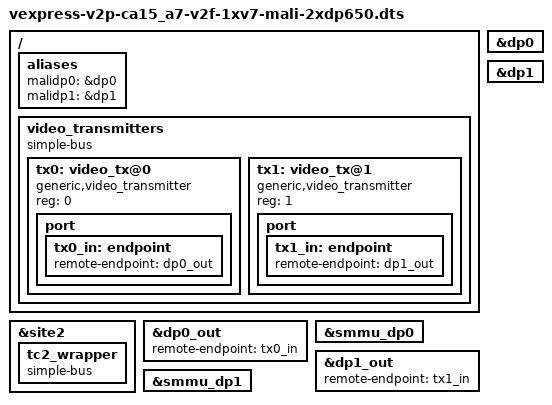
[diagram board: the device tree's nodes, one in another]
/*
 * ARM Versatile Express development platform with an A15x2 A7x3 CoreTile
 * and a single Virtex 7 LogicTile.
 * Configured for a bitfile containing a dual-display DP650 and
 * corresponding MMU-500s
 */

#include "vexpress-v2p-ca15_a7.dts"

/ {
	aliases {
		malidp0 = &dp0;
		malidp1 = &dp1;
	};

	video_transmitters {
		compatible = "simple-bus";
		#address-cells = <1>;
		#size-cells = <0>;

		tx0: video_tx@0 {
			compatible = "generic,video_transmitter";
			reg = <0>;
			port {
				tx0_in: endpoint {
					remote-endpoint = <&dp0_out>;
				};
			};
		};

		tx1: video_tx@1 {
			compatible = "generic,video_transmitter";
			reg = <1>;
			port {
				tx1_in: endpoint {
					remote-endpoint = <&dp1_out>;
				};
			};
		};
	};
};

&site2 {
	tc2_wrapper {
		compatible = "simple-bus";
		#address-cells = <1>;
		#size-cells = <1>;
		/*
		 * On VE TC2, all of the APB slaves are shifted up to
		 * 0x70000000.
		 * So we map 0 to (0x40000000 + 0x30000000)
		 */
		ranges = <0 0x30000000 0x10000000>;

		/include/ "v2f-1xv7-malidp-framework.dtsi"
		/include/ "v2f-1xv7-malidp-dp650.dtsi"
	};
};

/* Configure DP0 with test-transmitter */
&dp0 {
	status = "okay";
};

&dp0_out {
	remote-endpoint = <&tx0_in>;
};

&smmu_dp0 {
	status = "okay";
};

/* Configure DP1 with test-transmitter */
&dp1 {
	status = "okay";
};

&dp1_out {
	remote-endpoint = <&tx1_in>;
};

&smmu_dp1 {
	status = "okay";
};
